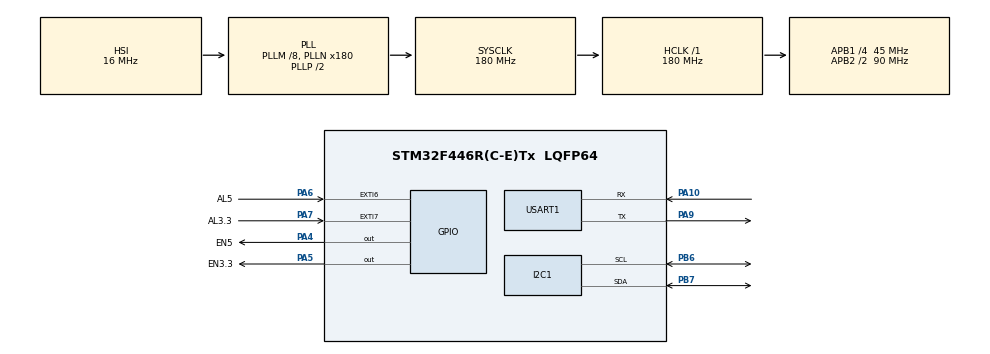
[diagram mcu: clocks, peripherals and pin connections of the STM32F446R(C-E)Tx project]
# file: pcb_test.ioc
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Mcu.Family=STM32F4
Mcu.Name=STM32F446R(C-E)Tx
Mcu.Package=LQFP64
NVIC.PriorityGroup=NVIC_PRIORITYGROUP_4
PA10.Mode=Asynchronous
PA10.Signal=USART1_RX
PA4.GPIO_Label=EN5
PA4.GPIO_ModeDefaultOutputPP=GPIO_MODE_OUTPUT_OD
PA4.GPIO_PuPd=GPIO_NOPULL
PA4.Signal=GPIO_Output
PA5.GPIO_Label=EN3.3
PA5.GPIO_ModeDefaultOutputPP=GPIO_MODE_OUTPUT_OD
PA5.GPIO_PuPd=GPIO_NOPULL
PA5.Signal=GPIO_Output
PA6.GPIO_Label=AL5
PA6.GPIO_ModeDefaultEXTI=GPIO_MODE_IT_FALLING
PA6.GPIO_PuPd=GPIO_PULLUP
PA6.Signal=GPXTI6
PA7.GPIO_Label=AL3.3
PA7.GPIO_ModeDefaultEXTI=GPIO_MODE_IT_FALLING
PA7.GPIO_PuPd=GPIO_PULLUP
PA7.Signal=GPXTI7
PA9.Mode=Asynchronous
PA9.Signal=USART1_TX
PB6.Mode=I2C
PB6.Signal=I2C1_SCL
PB7.Mode=I2C
PB7.Signal=I2C1_SDA
ProjectManager.HeapSize=0x200
ProjectManager.StackSize=0x400
ProjectManager.TargetToolchain=STM32CubeIDE
RCC.AHBFreq_Value=180000000
RCC.APB1CLKDivider=RCC_HCLK_DIV4
RCC.APB1Freq_Value=45000000
RCC.APB1TimFreq_Value=90000000
RCC.APB2CLKDivider=RCC_HCLK_DIV2
RCC.APB2Freq_Value=90000000
RCC.APB2TimFreq_Value=180000000
RCC.CortexFreq_Value=180000000
RCC.HCLKFreq_Value=180000000
RCC.PLLM=8
RCC.PLLN=180
RCC.SYSCLKFreq_VALUE=180000000
RCC.SYSCLKSource=RCC_SYSCLKSOURCE_PLLCLK
RCC.USBFreq_Value=180000000
RCC.VCOOutputFreq_Value=360000000
USART1.VirtualMode=VM_ASYNC
board=custom

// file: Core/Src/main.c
/* USER CODE BEGIN Header */
/**
  ******************************************************************************
  * @file           : main.c
  * @brief          : Main program body
  ******************************************************************************
  * @attention
  *
  * Copyright (c) 2026 STMicroelectronics.
  * All rights reserved.
  *
  * This software is licensed under terms that can be found in the LICENSE file
  * in the root directory of this software component.
  * If no LICENSE file comes with this software, it is provided AS-IS.
  *
  ******************************************************************************
  */
/* USER CODE END Header */
#include "main.h"

/* USER CODE BEGIN Includes */
#include<cstdio.h>
#include<cstdint.h>
/* USER CODE END Includes */

I2C_HandleTypeDef hi2c1;

UART_HandleTypeDef huart1;

void SystemClock_Config(void);
static void MX_GPIO_Init(void);
static void MX_I2C1_Init(void);
static void MX_USART1_UART_Init(void);

/* USER CODE BEGIN 0 */
// Send printf to uart1
extern "C" int _write(int fd, char *ptr, int len)
{
  if (fd == 1 || fd == 2) {
    if (HAL_UART_Transmit(&huart1,
                           (uint8_t *)ptr,
                           len,
                           HAL_MAX_DELAY) == HAL_OK)
      return len;
  }
  return -1;
}

/* USER CODE END 0 */

extern "C" int main(void)
{

  /* MCU Configuration--------------------------------------------------------*/

  /* Reset of all peripherals, Initializes the Flash interface and the Systick. */
  HAL_Init();

  /* Configure the system clock */
  SystemClock_Config();

  /* Initialize all configured peripherals */
  MX_GPIO_Init();
  MX_I2C1_Init();
  MX_USART1_UART_Init();
  /* USER CODE BEGIN 2 */
  //byte address=0x01;

  /* USER CODE END 2 */

  /* Infinite loop */
  /* USER CODE BEGIN WHILE */
  while (1)
  {
	  for(uint8_t address = 0x01; address < 0x7f; address++){
		  if(HAL_I2C_IsDeviceReady(&hi2c1, (address<<1) ,3,100)==HAL_OK){
			 printf("device found at address 0x%02X\r\n",address);
		  }
		  HAL_Delay(10);
	  }
    /* USER CODE END WHILE */

  }
}

void SystemClock_Config(void)
{
  RCC_OscInitTypeDef RCC_OscInitStruct = {0};
  RCC_ClkInitTypeDef RCC_ClkInitStruct = {0};

  /** Configure the main internal regulator output voltage
  */
  __HAL_RCC_PWR_CLK_ENABLE();
  __HAL_PWR_VOLTAGESCALING_CONFIG(PWR_REGULATOR_VOLTAGE_SCALE1);

  /** Initializes the RCC Oscillators according to the specified parameters
  * in the RCC_OscInitTypeDef structure.
  */
  RCC_OscInitStruct.OscillatorType = RCC_OSCILLATORTYPE_HSI;
  RCC_OscInitStruct.HSIState = RCC_HSI_ON;
  RCC_OscInitStruct.HSICalibrationValue = RCC_HSICALIBRATION_DEFAULT;
  RCC_OscInitStruct.PLL.PLLState = RCC_PLL_ON;
  RCC_OscInitStruct.PLL.PLLSource = RCC_PLLSOURCE_HSI;
  RCC_OscInitStruct.PLL.PLLM = 8;
  RCC_OscInitStruct.PLL.PLLN = 180;
  RCC_OscInitStruct.PLL.PLLP = RCC_PLLP_DIV2;
  RCC_OscInitStruct.PLL.PLLQ = 2;
  RCC_OscInitStruct.PLL.PLLR = 2;
  if (HAL_RCC_OscConfig(&RCC_OscInitStruct) != HAL_OK)
  {
    Error_Handler();
  }

  /** Activate the Over-Drive mode
  */
  if (HAL_PWREx_EnableOverDrive() != HAL_OK)
  {
    Error_Handler();
  }

  /** Initializes the CPU, AHB and APB buses clocks
  */
  RCC_ClkInitStruct.ClockType = RCC_CLOCKTYPE_HCLK|RCC_CLOCKTYPE_SYSCLK
                              |RCC_CLOCKTYPE_PCLK1|RCC_CLOCKTYPE_PCLK2;
  RCC_ClkInitStruct.SYSCLKSource = RCC_SYSCLKSOURCE_PLLCLK;
  RCC_ClkInitStruct.AHBCLKDivider = RCC_SYSCLK_DIV1;
  RCC_ClkInitStruct.APB1CLKDivider = RCC_HCLK_DIV4;
  RCC_ClkInitStruct.APB2CLKDivider = RCC_HCLK_DIV2;

  if (HAL_RCC_ClockConfig(&RCC_ClkInitStruct, FLASH_LATENCY_5) != HAL_OK)
  {
    Error_Handler();
  }
}

static void MX_I2C1_Init(void)
{

  hi2c1.Instance = I2C1;
  hi2c1.Init.ClockSpeed = 100000;
  hi2c1.Init.DutyCycle = I2C_DUTYCYCLE_2;
  hi2c1.Init.OwnAddress1 = 0;
  hi2c1.Init.AddressingMode = I2C_ADDRESSINGMODE_7BIT;
  hi2c1.Init.DualAddressMode = I2C_DUALADDRESS_DISABLE;
  hi2c1.Init.OwnAddress2 = 0;
  hi2c1.Init.GeneralCallMode = I2C_GENERALCALL_DISABLE;
  hi2c1.Init.NoStretchMode = I2C_NOSTRETCH_DISABLE;
  if (HAL_I2C_Init(&hi2c1) != HAL_OK)
  {
    Error_Handler();
  }

}

static void MX_USART1_UART_Init(void)
{

  huart1.Instance = USART1;
  huart1.Init.BaudRate = 115200;
  huart1.Init.WordLength = UART_WORDLENGTH_8B;
  huart1.Init.StopBits = UART_STOPBITS_1;
  huart1.Init.Parity = UART_PARITY_NONE;
  huart1.Init.Mode = UART_MODE_TX_RX;
  huart1.Init.HwFlowCtl = UART_HWCONTROL_NONE;
  huart1.Init.OverSampling = UART_OVERSAMPLING_16;
  if (HAL_UART_Init(&huart1) != HAL_OK)
  {
    Error_Handler();
  }

}

static void MX_GPIO_Init(void)
{
  GPIO_InitTypeDef GPIO_InitStruct = {0};

  /* GPIO Ports Clock Enable */
  __HAL_RCC_GPIOA_CLK_ENABLE();
  __HAL_RCC_GPIOB_CLK_ENABLE();

  /*Configure GPIO pin Output Level */
  HAL_GPIO_WritePin(GPIOA, EN5_Pin|EN3_3_Pin, GPIO_PIN_RESET);

  /*Configure GPIO pins : EN5_Pin EN3_3_Pin */
  GPIO_InitStruct.Pin = EN5_Pin|EN3_3_Pin;
  GPIO_InitStruct.Mode = GPIO_MODE_OUTPUT_OD;
  GPIO_InitStruct.Pull = GPIO_NOPULL;
  GPIO_InitStruct.Speed = GPIO_SPEED_FREQ_LOW;
  HAL_GPIO_Init(GPIOA, &GPIO_InitStruct);

  /*Configure GPIO pins : AL5_Pin AL3_3_Pin */
  GPIO_InitStruct.Pin = AL5_Pin|AL3_3_Pin;
  GPIO_InitStruct.Mode = GPIO_MODE_IT_FALLING;
  GPIO_InitStruct.Pull = GPIO_PULLUP;
  HAL_GPIO_Init(GPIOA, &GPIO_InitStruct);

}

void Error_Handler(void)
{
  __disable_irq();
  while (1)
  {
  }
}
